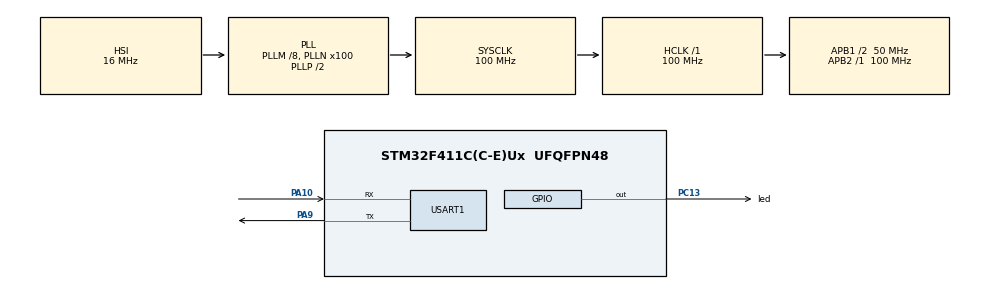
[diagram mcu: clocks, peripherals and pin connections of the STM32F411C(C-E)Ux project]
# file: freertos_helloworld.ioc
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FREERTOS.Tasks01=defaultTask,24,128,StartDefaultTask,Default,NULL,Dynamic,NULL,NULL
Mcu.Family=STM32F4
Mcu.Name=STM32F411C(C-E)Ux
Mcu.Package=UFQFPN48
NVIC.PriorityGroup=NVIC_PRIORITYGROUP_4
NVIC.TIM1_UP_TIM10_IRQn=true\:15\:0\:false\:false\:true\:false\:false\:true\:true
NVIC.TimeBase=TIM1_UP_TIM10_IRQn
NVIC.TimeBaseIP=TIM1
PA10.Mode=Asynchronous
PA10.Signal=USART1_RX
PA13.Mode=Serial_Wire
PA13.Signal=SYS_JTMS-SWDIO
PA14.Mode=Serial_Wire
PA14.Signal=SYS_JTCK-SWCLK
PA9.Mode=Asynchronous
PA9.Signal=USART1_TX
PC13-ANTI_TAMP.GPIO_Label=led
PC13-ANTI_TAMP.Signal=GPIO_Output
PC14-OSC32_IN.Mode=LSE-External-Oscillator
PC14-OSC32_IN.Signal=RCC_OSC32_IN
PC15-OSC32_OUT.Mode=LSE-External-Oscillator
PC15-OSC32_OUT.Signal=RCC_OSC32_OUT
PH0\ -\ OSC_IN.Mode=HSE-External-Oscillator
PH0\ -\ OSC_IN.Signal=RCC_OSC_IN
PH1\ -\ OSC_OUT.Mode=HSE-External-Oscillator
PH1\ -\ OSC_OUT.Signal=RCC_OSC_OUT
ProjectManager.HeapSize=0x200
ProjectManager.StackSize=0x400
ProjectManager.TargetToolchain=MDK-ARM V5
RCC.48MHZClocksFreq_Value=50000000
RCC.AHBFreq_Value=100000000
RCC.APB1CLKDivider=RCC_HCLK_DIV2
RCC.APB1Freq_Value=50000000
RCC.APB1TimFreq_Value=100000000
RCC.APB2Freq_Value=100000000
RCC.APB2TimFreq_Value=100000000
RCC.CortexFreq_Value=100000000
RCC.HCLKFreq_Value=100000000
RCC.HSE_VALUE=25000000
RCC.HSI_VALUE=16000000
RCC.PLLM=8
RCC.PLLN=100
RCC.SYSCLKFreq_VALUE=100000000
RCC.SYSCLKSource=RCC_SYSCLKSOURCE_PLLCLK
RCC.VCOOutputFreq_Value=200000000
USART1.VirtualMode=VM_ASYNC
VP_FREERTOS_VS_CMSIS_V2.Mode=CMSIS_V2
VP_SYS_VS_tim1.Mode=TIM1
board=custom

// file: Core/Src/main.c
/* USER CODE BEGIN Header */
/**
  ******************************************************************************
  * @file           : main.c
  * @brief          : Main program body
  ******************************************************************************
  * @attention
  *
  * Copyright (c) 2025 STMicroelectronics.
  * All rights reserved.
  *
  * This software is licensed under terms that can be found in the LICENSE file
  * in the root directory of this software component.
  * If no LICENSE file comes with this software, it is provided AS-IS.
  *
  ******************************************************************************
  */
/* USER CODE END Header */
#include "main.h"
#include "cmsis_os.h"
#include "usart.h"
#include "gpio.h"

/* USER CODE BEGIN Includes */
#include <stdio.h>
/* USER CODE END Includes */

void SystemClock_Config(void);
void MX_FREERTOS_Init(void);

/* USER CODE BEGIN 0 */
#ifdef __GNUC__
#define PUTCHAR_PROTOTYPE int _io_putchar(int ch)
#else
#define PUTCHAR_PROTOTYPE int fputc(int ch, FILE *f)
#endif /* __GNUC__*/

/******************************************************************
 *@brief  Retargets the C library printf function to the USART.
 *@param  None
 *@retval None
 ******************************************************************/
PUTCHAR_PROTOTYPE
{
    // vTaskSuspendAll();
    HAL_UART_Transmit(&huart1, (uint8_t *)&ch, 1, HAL_MAX_DELAY);
    // xTaskResumeAll();
    return ch;
}
/* USER CODE END 0 */

int main(void)
{

  /* MCU Configuration--------------------------------------------------------*/

  /* Reset of all peripherals, Initializes the Flash interface and the Systick. */
  HAL_Init();

  /* Configure the system clock */
  SystemClock_Config();

  /* Initialize all configured peripherals */
  MX_GPIO_Init();
  MX_USART1_UART_Init();

  /* Init scheduler */
  osKernelInitialize();  /* Call init function for freertos objects (in freertos.c) */
  MX_FREERTOS_Init();

  /* Start scheduler */
  osKernelStart();
  /* We should never get here as control is now taken by the scheduler */
  /* Infinite loop */
  while (1)
  {

  }
}

void SystemClock_Config(void)
{
  RCC_OscInitTypeDef RCC_OscInitStruct = {0};
  RCC_ClkInitTypeDef RCC_ClkInitStruct = {0};

  /** Configure the main internal regulator output voltage
  */
  __HAL_RCC_PWR_CLK_ENABLE();
  __HAL_PWR_VOLTAGESCALING_CONFIG(PWR_REGULATOR_VOLTAGE_SCALE1);

  /** Initializes the RCC Oscillators according to the specified parameters
  * in the RCC_OscInitTypeDef structure.
  */
  RCC_OscInitStruct.OscillatorType = RCC_OSCILLATORTYPE_HSI;
  RCC_OscInitStruct.HSIState = RCC_HSI_ON;
  RCC_OscInitStruct.HSICalibrationValue = RCC_HSICALIBRATION_DEFAULT;
  RCC_OscInitStruct.PLL.PLLState = RCC_PLL_ON;
  RCC_OscInitStruct.PLL.PLLSource = RCC_PLLSOURCE_HSI;
  RCC_OscInitStruct.PLL.PLLM = 8;
  RCC_OscInitStruct.PLL.PLLN = 100;
  RCC_OscInitStruct.PLL.PLLP = RCC_PLLP_DIV2;
  RCC_OscInitStruct.PLL.PLLQ = 4;
  if (HAL_RCC_OscConfig(&RCC_OscInitStruct) != HAL_OK)
  {
    Error_Handler();
  }

  /** Initializes the CPU, AHB and APB buses clocks
  */
  RCC_ClkInitStruct.ClockType = RCC_CLOCKTYPE_HCLK|RCC_CLOCKTYPE_SYSCLK
                              |RCC_CLOCKTYPE_PCLK1|RCC_CLOCKTYPE_PCLK2;
  RCC_ClkInitStruct.SYSCLKSource = RCC_SYSCLKSOURCE_PLLCLK;
  RCC_ClkInitStruct.AHBCLKDivider = RCC_SYSCLK_DIV1;
  RCC_ClkInitStruct.APB1CLKDivider = RCC_HCLK_DIV2;
  RCC_ClkInitStruct.APB2CLKDivider = RCC_HCLK_DIV1;

  if (HAL_RCC_ClockConfig(&RCC_ClkInitStruct, FLASH_LATENCY_3) != HAL_OK)
  {
    Error_Handler();
  }
}

void HAL_TIM_PeriodElapsedCallback(TIM_HandleTypeDef *htim)
{
  if (htim->Instance == TIM1) {
    HAL_IncTick();
  }
}

void Error_Handler(void)
{
  __disable_irq();
  while (1)
  {
  }
}

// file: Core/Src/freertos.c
/* USER CODE BEGIN Header */
/**
 ******************************************************************************
 * File Name          : freertos.c
 * Description        : Code for freertos applications
 ******************************************************************************
 * @attention
 *
 * Copyright (c) 2025 STMicroelectronics.
 * All rights reserved.
 *
 * This software is licensed under terms that can be found in the LICENSE file
 * in the root directory of this software component.
 * If no LICENSE file comes with this software, it is provided AS-IS.
 *
 ******************************************************************************
 */
/* USER CODE END Header */

#include "FreeRTOS.h"
#include "task.h"
#include "main.h"
#include "cmsis_os.h"

/* USER CODE BEGIN Includes */
#include <stdio.h>

#include "queue.h"

#include "bsp_led_driver.h"
#include "bsp_led_handler.h"
/* USER CODE END Includes */

/* USER CODE BEGIN PD */
#define HANLDER_1_DEBUG           1
// uint test of led operations
led_status_t led_on_myown (void)
{
    HAL_GPIO_WritePin(led_GPIO_Port, led_Pin, GPIO_PIN_SET);
    printf("LED ON\r\n");
    return LED_OK;
}
led_status_t led_off_myown (void)
{
    HAL_GPIO_WritePin(led_GPIO_Port, led_Pin, GPIO_PIN_RESET);
    printf("LED OFF\r\n");
    return LED_OK;
}
led_operations_t led_operations_myown = {
    .pf_led_on  = led_on_myown,
    .pf_led_off = led_off_myown,
};

led_status_t pf_get_time_ms_myown ( uint32_t * const time_stamp)
{
    printf("get time now [%lu]ms\r\n", HAL_GetTick());
    *time_stamp = HAL_GetTick();
    return LED_OK;
}
time_base_ms_t time_base_ms_myown = {
    .pf_get_time_ms = pf_get_time_ms_myown,
};

led_status_t pf_os_delay_ms_myown ( const uint32_t delay )
{
    // for ( uint32_t i = 0; i < 1000 * delay; i++ )
    // {

    // }
    osDelay(delay);
    printf("delay [%d]ms finished\r\n", delay);
    return LED_OK;
}
os_delay_t os_delay_myown = {
    .pf_os_delay_ms = pf_os_delay_ms_myown,
};

// Self test :: driver-layer-test
void Test1()
{
    printf("Hello World!\r\n");
    bsp_led_driver_t led1;
    led_driver_inst(&led1,
                    &led_operations_myown,
                    &os_delay_myown,
                    &time_base_ms_myown);
    led1.pf_led_controller(&led1, 1000, 10, PROPORTION_1_1);
    printf("Hello World2!\r\n");
}

led_status_t os_delay_ms_handler_1 ( const uint32_t delay_time )
{
    osDelay(delay_time);
#if HANLDER_1_DEBUG
    printf("delay [%d]ms finished finished\r\n", delay_time);
#endif // HANLDER_1_DEBUG
    return LED_OK;
}
os_delay_t handler_1_os_delay = {
    .pf_os_delay_ms = os_delay_ms_handler_1,
};

led_handler_status_t os_queue_create_handler_1 (
                                                   uint32_t const     item_num,
                                                   uint32_t const    item_size,
                                                   void **  const queue_handler
                                               )
{
#if HANLDER_1_DEBUG
    printf("os_queue_create_handler_1 kick off\r\n");
#endif // HANLDER_1_DEBUG
    QueueHandle_t temp_queue_handler = NULL;

    temp_queue_handler = xQueueCreate(item_num, item_size);
    if (NULL == temp_queue_handler)
    {
        return HANDLER_ERRORRESOURCE;
    }
    else
    {
        *queue_handler = (void *)temp_queue_handler;
        return HANDLER_OK;
    }
}

led_handler_status_t os_queue_put_handler_1 (
                                                void *  const queue_handler,
                                                void *  const          item,
                                                uint32_t             timeout
                                            )
{
#if HANLDER_1_DEBUG
    printf("os_queue_put_handler_1 kick off\r\n");
#endif // HANLDER_1_DEBUG
    led_handler_status_t ret = HANDLER_OK;
    if (
        NULL == queue_handler ||
        NULL == item          ||
        timeout > portMAX_DELAY
       )
    {
        return HANDLER_ERRORPARAMETER;
    }
    else
    {
        if ( pdTRUE != xQueueSend((QueueHandle_t)queue_handler,
                                                         item,
                                                     timeout) )
        {
            ret = HANDLER_ERROR;
            return ret;
        }
    }
    return ret;
}

led_handler_status_t os_queue_get_handler_1 (
                                                void *  const queue_handler,
                                                void *  const           msg,
                                                uint32_t             timeout
                                             )
{
#if HANLDER_1_DEBUG
    printf("os_queue_get_handler_1 kick off\r\n");
#endif // HANLDER_1_DEBUG
    led_handler_status_t ret = HANDLER_OK;
    if (
        NULL == queue_handler ||
        NULL == msg          ||
        timeout > portMAX_DELAY
       )
    {
        return HANDLER_ERRORPARAMETER;
    }
    else
    {
        if ( pdTRUE != xQueueReceive((QueueHandle_t)queue_handler,
                                                              msg,
                                                        timeout) )
        {
            ret = HANDLER_ERROR;
            return ret;
        }
    }
    return ret;
}

led_handler_status_t os_queue_delete_hanler_1 (void *  const  queue_handler)
{
#if HANLDER_1_DEBUG
    printf("os_queue_delete_hanler_1 kick off\r\n");
#endif // HANLDER_1_DEBUG
    if (NULL == queue_handler)
    {
        return HANDLER_ERRORPARAMETER;
    }

    vQueueDelete((QueueHandle_t)queue_handler);
    return HANDLER_OK;
}

handler_os_queue_t handler1_os_queue = {
    .pf_os_queue_create = os_queue_create_handler_1,
    .pf_os_queue_put    = os_queue_put_handler_1,
    .pf_os_queue_get    = os_queue_get_handler_1,
    .pf_os_queue_delete = os_queue_delete_hanler_1,
};

led_handler_status_t os_critical_enter_handler_1 ( void )
{
    vPortEnterCritical();
    return HANDLER_OK;
}
led_handler_status_t os_critical_exit_handler_1 ( void )
{
    vPortExitCritical();
    return HANDLER_OK;
}
handler_os_critical_t handler1_os_critical = {
    .pf_os_critical_enter = os_critical_enter_handler_1,
    .pf_os_critical_exit  = os_critical_exit_handler_1,
};

led_handler_status_t get_time_ms_handler_1 ( uint32_t * const os_tick)
{
    if (NULL == os_tick)
    {
#if HANLDER_1_DEBUG
        printf("get_time_ms_handler_1 input parameter error\r\n");
#endif // HANLDER_1_DEBUG
        return HANDLER_ERRORPARAMETER;
    }
    *os_tick = HAL_GetTick();
    return HANDLER_OK;
}
handler_time_base_ms_t time_base_ms_handler_1 = {
    .pf_get_time_ms = get_time_ms_handler_1,
};

// Self test :: driver-layer-test
void Test2()
{
    printf("Hello World!\r\n");
//******************************** Handler **********************************//
    led_handler_status_t ret = HANDLER_OK;
    bsp_led_handler_t handler_1;
    ret = led_handler_inst(
                           &handler_1,
                           &handler_1_os_delay,
                           &handler1_os_queue,
                           &handler1_os_critical,
                           &time_base_ms_handler_1
                          );

//******************************** Driver ***********************************//
    bsp_led_driver_t led1;
    led_driver_inst(&led1,
                    &led_operations_myown,
                    &os_delay_myown,
                    &time_base_ms_myown);

    bsp_led_driver_t led2;
    led_driver_inst(&led2,
                    &led_operations_myown,
                    &os_delay_myown,
                    &time_base_ms_myown);
    led1.pf_led_controller(&led1, 5, 30, PROPORTION_1_1);
    led2.pf_led_controller(&led2, 2, 10, PROPORTION_1_3);

//*************************** Intergrated Test ******************************//
    led_index_t handler_1_led_index = LED_NOT_INITIALIZED;
    ret = handler_1.pf_led_register(
                                &handler_1,
                                &led1,
                                &handler_1_led_index
                                  );
    printf("The return of handler_1.pf_led_register is [%d]\r\n", ret);
    printf("LED registered with index [%lu]\r\n", handler_1_led_index + 1);

    ret = handler_1.pf_led_register(
                                &handler_1,
                                &led2,
                                &handler_1_led_index
                                  );
    printf("The return of handler_1.pf_led_register is [%d]\r\n", ret);
    printf("LED registered with index [%lu]\r\n", handler_1_led_index + 1);

    printf("Hello World2!\r\n");
}

/* USER CODE END PD */

/* Definitions for defaultTask */
osThreadId_t defaultTaskHandle;
const osThreadAttr_t defaultTask_attributes = {
    .name = "defaultTask",
    .stack_size = 128 * 4,
    .priority = (osPriority_t)osPriorityNormal,
};

void StartDefaultTask(void *argument);

void MX_FREERTOS_Init(void); /* (MISRA C 2004 rule 8.1) */

void MX_FREERTOS_Init(void)
{

    /* Create the thread(s) */
    /* creation of defaultTask */
    defaultTaskHandle   = osThreadNew(StartDefaultTask,
                                      NULL,
                                      &defaultTask_attributes);

}

void StartDefaultTask(void *argument)
{
    /* USER CODE BEGIN StartDefaultTask */
    // Self test
    Test2();

    /* Infinite loop */
    for (;;)
    {

        osDelay(100);
    }
    /* USER CODE END StartDefaultTask */
}
